# ESP32-S2 register map
Vendor: ESPRESSIF SYSTEMS (SHANGHAI) CO., LTD.; Series: ESP32 S-Series; File version: 20
CPU: Xtensa LX7 r0p0, little endian, no MPU, no FPU, 0 interrupt priority bits
Address unit: 32 bits
Registers are 32-bit, read-write, reset 0x0 unless marked. A register's access mark holds for its fields unless they carry their own. Offsets are from the block's base; [hi:lo] are bit positions; {n}, {i} and the like mark numbered series.

## NRX — NRX Peripheral
Base 0x3F41CC00
0xD4 NRXPD_CTRL 4-bit — NRX Power Down Control Register
  [7] CHAN_EST_FORCE_PU — Force Power Up for Channel Estimation
  [6] CHAN_EST_FORCE_PD — Force Power Down for Channel Estimation
  [5] RX_ROT_FORCE_PU — Force Power Up for RX Rotation
  [4] RX_ROT_FORCE_PD — Force Power Down for RX Rotation
  [3] VIT_FORCE_PU — Force Power Up for Viterbi Decoder
  [2] VIT_FORCE_PD — Force Power Down for Viterbi Decoder
  [1] DEMAP_FORCE_PU — Force Power Up for Demapper
  [0] DEMAP_FORCE_PD — Force Power Down for Demapper

## MMU_TABLE — External memory cache MMU table
Base 0x61801000
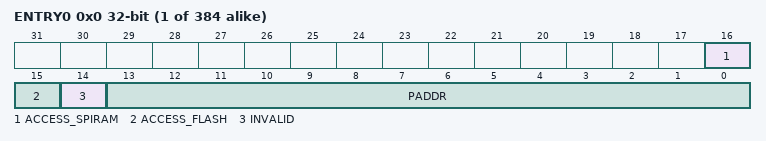
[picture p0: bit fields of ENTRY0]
{0x0+4i} ENTRY{i} (i=0..383) — MMU table entry
  [16] ACCESS_SPIRAM — Map to SPIRAM/PSRAM when set
  [15] ACCESS_FLASH — Map to flash when set
  [14] INVALID — Set to mark this entry invalid
  [13:0] PADDR — Physical page number

## GPIO_SD — Sigma-Delta Modulation
Base 0x3F404F00
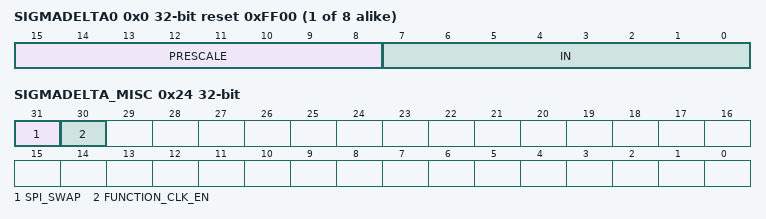
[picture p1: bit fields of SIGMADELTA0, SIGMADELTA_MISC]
{0x0+4i} SIGMADELTA{i} (i=0..7) reset 0xFF00 — Duty-cycle configuration register of SDM{i}
  [15:8] PRESCALE — This field is used to set a divider value to divide APB clock.
  [7:0] IN — This field is used to configure the duty cycle of sigma delta modulation output.
0x20 CLOCK_GATE — Clock gating configuration register
  [31] CLK_EN — Clock enable bit of configuration registers for sigma delta modulation.
0x24 SIGMADELTA_MISC — MISC register
  [31] SPI_SWAP — Reserved.
  [30] FUNCTION_CLK_EN — Clock enable bit of sigma delta modulation.
0x28 VERSION — Version control register

## FE2 — FE2 Peripheral
Base 0x3F405000
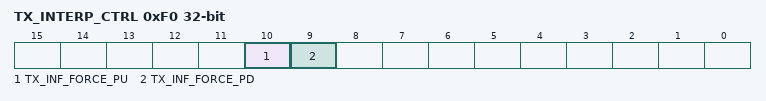
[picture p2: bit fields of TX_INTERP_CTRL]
0xF0 TX_INTERP_CTRL — FE2 TX Interpolation Control Register
  [10] TX_INF_FORCE_PU — Force Power Up field
  [9] TX_INF_FORCE_PD — Force Power Down field

## FE — FE Peripheral
Base 0x3F406000
0x90 GEN_CTRL 2-bit — FE General Control Register
  [5] IQ_EST_FORCE_PU — Force Power Up for IQ Estimation
  [4] IQ_EST_FORCE_PD — Force Power Down for IQ Estimation

## HMAC — HMAC (Hash-based Message Authentication Code) Accelerator
Base 0x6003E000
0x40 SET_START wo — HMAC start control register
  [0] SET_START — Set this bit to enable HMAC.
0x44 SET_PARA_PURPOSE wo — HMAC parameter configuration register
  [3:0] PURPOSE_SET — Set hmac purpose.
0x48 SET_PARA_KEY wo — HMAC key configuration register
  [2:0] KEY_SET — Select hmac key.
0x4C SET_PARA_FINISH wo — HMAC configuration completion register
  [0] SET_PARA_END — Set this bit to finish HMAC configuration.
0x50 SET_MESSAGE_ONE wo — HMAC one message control register
  [0] SET_TEXT_ONE — Call SHA to calculate one message block.
0x54 SET_MESSAGE_ING wo — HMAC message continue register
  [0] SET_TEXT_ING — Set this bit to show there are still some message blocks to be processed.
0x58 SET_MESSAGE_END wo — HMAC message end register
  [0] SET_TEXT_END — Set this bit to start hardware padding.
0x5C SET_RESULT_FINISH wo — HMAC read result completion register
  [0] SET_RESULT_END — Set this bit to end upstream and clear the calculation result.
0x60 SET_INVALIDATE_JTAG wo — Invalidate JTAG result register
  [0] SET_INVALIDATE_JTAG — Set this bit to clear calculation results in JTAG re-enable function under downstream mode.
0x64 SET_INVALIDATE_DS wo — Invalidate digital signature result register
  [0] SET_INVALIDATE_DS — Set this bit to clear calculation results in DS function under downstream mode.
0x68 QUERY_ERROR ro — The matching result between key and purpose user configured
  [0] QUERY_CHECK — Hmac error status. 0: hmac key and purpose match. 1: error.
0x6C QUERY_BUSY ro — The busy state of HMAC module
  [0] BUSY_STATE — The state of Hmac. 1'b0: idle. 1'b1: busy.
{0x80+4i} WR_MESSAGE_{i} (i=0..15) wo — Message register {i}
  [31:0] WDATA — Store the %sth 32-bit of message.
{0xC0+4i} RD_RESULT_{i} (i=0..7) ro — Hash result register {i}
  [31:0] RDATA — Read the %sth 32-bit of hash result.
0xF0 SET_MESSAGE_PAD wo — Software padding register
  [0] SET_TEXT_PAD — Set this bit to let software do padding job.
0xF4 ONE_BLOCK wo — One block message register.
  [0] SET_ONE_BLOCK — Set this bit to show no padding is required.
0xF8 DATE — Version control register
